AUTOSAR XML (schema 00050)
package /FCADT/ComponentTypes
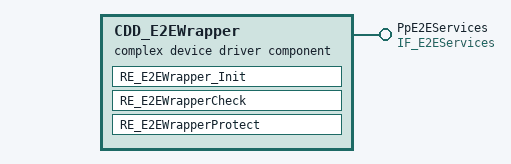
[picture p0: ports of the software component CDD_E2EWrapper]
  complex device driver sw component type CDD_E2EWrapper
    provide port PpE2EServices: provided-com-specs=[{operation=ME_E2E_Check, queue-length=1}, {operation=ME_E2E_Protect, queue-length=1}], provided-interface=IF_E2EServices
    behavior CDD_E2EWrapper_InternalBehavior: handle-termination-and-restart=NO-SUPPORT, port-api-option{enable-take-address=false, error-handling=NO-TRANSFORMER-ERROR-HANDLING, indirect-api=false, port=PpE2EServices}
      init event InitEvent: start-on-event=RE_E2EWrapper_Init
      operation invoked event OIT_RE_E2EWrapperCheck_PpE2EServices_ME_E2E_Check: start-on-event=RE_E2EWrapperCheck, operation=PpE2EServices.ME_E2E_Check
      operation invoked event OIT_RE_E2EWrapperProtect_PpE2EServices_ME_E2E_Protect: start-on-event=RE_E2EWrapperProtect, operation=PpE2EServices.ME_E2E_Protect
      runnable RE_E2EWrapper_Init
      runnable RE_E2EWrapperCheck: can-be-invoked-concurrently=true
      runnable RE_E2EWrapperProtect: can-be-invoked-concurrently=true
  swc implementation CDD_E2EWrapper_Implementation: programming-language=C, vendor-id=0, behavior=CDD_E2EWrapper_InternalBehavior
    code-descriptors:
      code Default: artifact-descriptors=autosar-engineering-object=category=SWSRC
